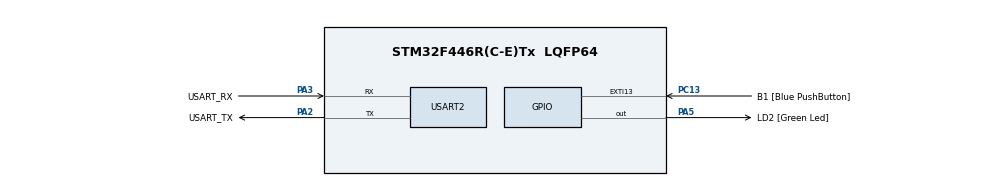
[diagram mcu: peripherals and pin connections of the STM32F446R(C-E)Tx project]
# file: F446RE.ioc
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Mcu.Family=STM32F4
Mcu.Name=STM32F446R(C-E)Tx
Mcu.Package=LQFP64
NVIC.PriorityGroup=NVIC_PRIORITYGROUP_0
PA13.GPIO_Label=TMS
PA13.Mode=Serial_Wire
PA13.Signal=SYS_JTMS-SWDIO
PA14.GPIO_Label=TCK
PA14.Mode=Serial_Wire
PA14.Signal=SYS_JTCK-SWCLK
PA2.GPIO_Label=USART_TX
PA2.Mode=Asynchronous
PA2.Signal=USART2_TX
PA3.GPIO_Label=USART_RX
PA3.Mode=Asynchronous
PA3.Signal=USART2_RX
PA5.GPIO_Label=LD2 [Green Led]
PA5.Signal=GPIO_Output
PB3.GPIO_Label=SWO
PB3.Signal=SYS_JTDO-SWO
PC13.GPIO_Label=B1 [Blue PushButton]
PC13.GPIO_ModeDefaultEXTI=GPIO_MODE_IT_FALLING
PC13.Signal=GPXTI13
PC14-OSC32_IN.Mode=LSE-External-Oscillator
PC14-OSC32_IN.Signal=RCC_OSC32_IN
PC15-OSC32_OUT.Mode=LSE-External-Oscillator
PC15-OSC32_OUT.Signal=RCC_OSC32_OUT
PH0-OSC_IN.Mode=HSE-External-Oscillator
PH0-OSC_IN.Signal=RCC_OSC_IN
PH1-OSC_OUT.Mode=HSE-External-Oscillator
PH1-OSC_OUT.Signal=RCC_OSC_OUT
ProjectManager.HeapSize=0x200
ProjectManager.StackSize=0x400
ProjectManager.TargetToolchain=CMake
RCC.48MHZClocksFreq_Value=84000000
RCC.AHBFreq_Value=84000000
RCC.APB1CLKDivider=RCC_HCLK_DIV2
RCC.APB1Freq_Value=42000000
RCC.APB1TimFreq_Value=84000000
RCC.APB2Freq_Value=84000000
RCC.APB2TimFreq_Value=84000000
RCC.CortexFreq_Value=84000000
RCC.FLatency-AdvancedSettings=FLASH_LATENCY_2
RCC.HCLKFreq_Value=84000000
RCC.HSE_VALUE=8000000
RCC.HSI_VALUE=16000000
RCC.PLLN=336
RCC.PLLP=RCC_PLLP_DIV4
RCC.SYSCLKFreq_VALUE=84000000
RCC.SYSCLKSource=RCC_SYSCLKSOURCE_PLLCLK
RCC.USBFreq_Value=168000000
RCC.VCOOutputFreq_Value=336000000
USART2.VirtualMode=VM_ASYNC
board=NUCLEO-F446RE

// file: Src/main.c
/* USER CODE BEGIN Header */
/**
  ******************************************************************************
  * @file           : main.c
  * @brief          : Main program body
  ******************************************************************************
  * @attention
  *
  * Copyright (c) 2025 STMicroelectronics.
  * All rights reserved.
  *
  * This software is licensed under terms that can be found in the LICENSE file
  * in the root directory of this software component.
  * If no LICENSE file comes with this software, it is provided AS-IS.
  *
  ******************************************************************************
  */
/* USER CODE END Header */
#include "main.h"
#include "usart.h"
#include "gpio.h"

/* USER CODE BEGIN Includes */

#include "stm32f4xx_it.h"

/* USER CODE END Includes */

void SystemClock_Config(void);

int main(void)
{

  /* USER CODE BEGIN 1 */

  uint32_t then = 0, now = 0;

  /* USER CODE END 1 */

  /* MCU Configuration--------------------------------------------------------*/

  /* Reset of all peripherals, Initializes the Flash interface and the Systick. */
  LL_APB2_GRP1_EnableClock(LL_APB2_GRP1_PERIPH_SYSCFG);
  LL_APB1_GRP1_EnableClock(LL_APB1_GRP1_PERIPH_PWR);

  /* System interrupt init*/
  NVIC_SetPriorityGrouping(NVIC_PRIORITYGROUP_0);

  /* Configure the system clock */
  SystemClock_Config();

  /* Initialize all configured peripherals */
  MX_GPIO_Init();
  MX_USART2_UART_Init();
  /* USER CODE BEGIN 2 */

  LL_SYSTICK_EnableIT();

  /* USER CODE END 2 */

  /* Infinite loop */
  while (1)
  {
    now = GetSysTickCounter();
    if(now - then >= 500) {
      LL_GPIO_TogglePin(LD2_GPIO_Port, LD2_Pin);
      then = now;
    }
  }
}

void SystemClock_Config(void)
{
  LL_FLASH_SetLatency(LL_FLASH_LATENCY_2);
  while(LL_FLASH_GetLatency()!= LL_FLASH_LATENCY_2)
  {
  }
  LL_PWR_SetRegulVoltageScaling(LL_PWR_REGU_VOLTAGE_SCALE3);
  LL_PWR_DisableOverDriveMode();
  LL_RCC_HSI_SetCalibTrimming(16);
  LL_RCC_HSI_Enable();

   /* Wait till HSI is ready */
  while(LL_RCC_HSI_IsReady() != 1)
  {

  }
  LL_RCC_PLL_ConfigDomain_SYS(LL_RCC_PLLSOURCE_HSI, LL_RCC_PLLM_DIV_16, 336, LL_RCC_PLLP_DIV_4);
  LL_RCC_PLL_Enable();

   /* Wait till PLL is ready */
  while(LL_RCC_PLL_IsReady() != 1)
  {

  }
  while (LL_PWR_IsActiveFlag_VOS() == 0)
  {
  }
  LL_RCC_SetAHBPrescaler(LL_RCC_SYSCLK_DIV_1);
  LL_RCC_SetAPB1Prescaler(LL_RCC_APB1_DIV_2);
  LL_RCC_SetAPB2Prescaler(LL_RCC_APB2_DIV_1);
  LL_RCC_SetSysClkSource(LL_RCC_SYS_CLKSOURCE_PLL);

   /* Wait till System clock is ready */
  while(LL_RCC_GetSysClkSource() != LL_RCC_SYS_CLKSOURCE_STATUS_PLL)
  {

  }
  LL_Init1msTick(84000000);
  LL_SetSystemCoreClock(84000000);
  LL_RCC_SetTIMPrescaler(LL_RCC_TIM_PRESCALER_TWICE);
}

void Error_Handler(void)
{
  __disable_irq();
  while (1)
  {
  }
}
